# ARMCM3 register map
Vendor: ARM Ltd.; Series: ARMCM; File version: 1.2
ARM 32-bit Cortex-M3 Microcontroller based device, CPU clock up to 80MHz, etc.
CPU: CM3 r1p1, little endian, no MPU, no FPU, 4 interrupt priority bits
Registers are 32-bit, read-write, reset 0x0 unless marked. A register's access mark holds for its fields unless they carry their own. Offsets are from the block's base; lines under a group give offsets from that group; [hi:lo] are bit positions; {n}, {i} and the like mark numbered series; 'fields as' and 'values as' point back to an identical list; <NAME> marks a mode.

## Memory map
0x40001000 WDT size 0x10 — Watchdog Timer
0xE000E000 NVIC size 0xF04 — Nested Vectored Interrupt Controller
0xE000E010 SysTick size 0x10 — 24Bit System Tick Timer for use in RTOS
0xE000ED00 SCB size 0x40 — System Control Block

## Interrupts
1 WDT

## SysTick — 24Bit System Tick Timer for use in RTOS
Base 0xE000E010
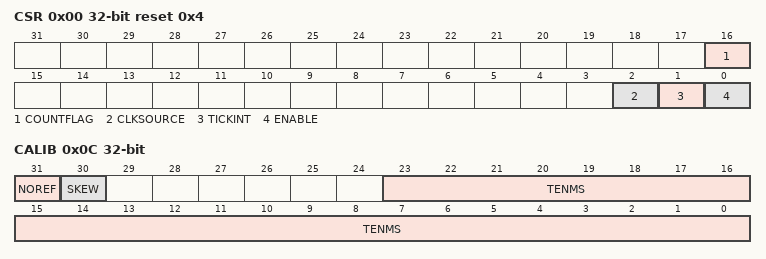
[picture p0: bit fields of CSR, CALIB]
0x00 CSR reset 0x4 — SysTick Control and Status Register
  [16] COUNTFLAG — SysTick counted to zero
  [2] CLKSOURCE — Source to count from
    0=External Clock; 1=CPU Clock
  [1] TICKINT — Generate Tick Interrupt
    0=Enable SysTick Exception; 1=Disable SysTick Exception
  [0] ENABLE — Enable SysTick Timer
    0=disabled; 1=enabled
0x04 RVR — SysTick Reload Value Register
  [23:0] RELOAD — Value to auto reload SysTick after reaching zero
0x08 CVR — SysTick Current Value Register
  [23:0] CURRENT — Current value
0x0C CALIB — SysTick Calibration Value Register
  [31] NOREF ro
    0=Ref Clk available; 1=Ref Clk not available
  [30] SKEW ro — Clock Skew
    0=10ms calibration value is exact; 1=10ms calibration value is inexact, because of the clock frequency
  [23:0] TENMS ro — Reload value to use for 10ms timing

## WDT — Watchdog Timer
Base 0x40001000
0x00 CSR reset 0x4 — Watchdog Control and Status Register

## NVIC — Nested Vectored Interrupt Controller
Base 0xE000E000
0x100 ISER0 — Irq 0 to 31 Set Enable Register
0x104 ISER1 — Irq 32 to 63 Set Enable Register
0x180 ICER0 — Irq 0 to 31 Clear Enable Register
0x184 ICER1 — Irq 32 to 63 Clear Enable Register
0x200 ISPR0 — Irq 0 to 31 Set Pending Register
0x204 ISPR1 — Irq 32 to 63 Set Pending Register
0x280 ICPR0 — Irq 0 to 31 Clear Pending Register
0x284 ICPR1 — Irq 32 to 63 Clear Pending Register
0x300 IABR0 — Irq 0 to 31 Active Status Register
0x304 IABR1 — Irq 32 to 63 Active Status Register
0x400 IPR0 — Irq 0 to 31 Priority-Level Register
0x404 IPR1 — Irq 32 to 63 Priority-Level Register
0xF00 STIR write — Software Trigger Interrupt Register

## Licence text in the file
ARM Limited (ARM) is supplying this software for use with Cortex-M processor based microcontroller, but can be equally used for other suitable processor architectures. This file can be freely distributed. Modifications to this file shall be clearly marked. . THIS SOFTWARE IS PROVIDED "AS IS". NO WARRANTIES, WHETHER EXPRESS, IMPLIED. OR STATUTORY, INCLUDING, BUT NOT LIMITED TO, IMPLIED WARRANTIES OF. MERCHANTABILITY AND FITNESS FOR A PARTICULAR PURPOSE APPLY TO THIS SOFTWARE. ARM SHALL NOT, IN ANY CIRCUMSTANCES, BE LIABLE FOR SPECIAL, INCIDENTAL, OR. CONSEQUENTIAL DAMAGES, FOR ANY REASON WHATSOEVER.

## Notices in the file
Copyright (C) 2012 ARM Limited. All rights reserved.
Purpose: System Viewer Description (SVD) Example (Schema Version 1.1)
This is a description of a none-existent and incomplete device
for demonstration purposes only.
Redistribution and use in source and binary forms, with or without
modification, are permitted provided that the following conditions are met:
- Redistributions of source code must retain the above copyright
notice, this list of conditions and the following disclaimer.
- Redistributions in binary form must reproduce the above copyright
notice, this list of conditions and the following disclaimer in the
documentation and/or other materials provided with the distribution.
- Neither the name of ARM nor the names of its contributors may be used
to endorse or promote products derived from this software without
specific prior written permission.
THIS SOFTWARE IS PROVIDED BY THE COPYRIGHT HOLDERS AND CONTRIBUTORS "AS IS"
AND ANY EXPRESS OR IMPLIED WARRANTIES, INCLUDING, BUT NOT LIMITED TO, THE
ARE DISCLAIMED. IN NO EVENT SHALL COPYRIGHT HOLDERS AND CONTRIBUTORS BE
LIABLE FOR ANY DIRECT, INDIRECT, INCIDENTAL, SPECIAL, EXEMPLARY, OR
CONSEQUENTIAL DAMAGES (INCLUDING, BUT NOT LIMITED TO, PROCUREMENT OF
SUBSTITUTE GOODS OR SERVICES; LOSS OF USE, DATA, OR PROFITS; OR BUSINESS
INTERRUPTION) HOWEVER CAUSED AND ON ANY THEORY OF LIABILITY, WHETHER IN
CONTRACT, STRICT LIABILITY, OR TORT (INCLUDING NEGLIGENCE OR OTHERWISE)
ARISING IN ANY WAY OUT OF THE USE OF THIS SOFTWARE, EVEN IF ADVISED OF THE
POSSIBILITY OF SUCH DAMAGE.
